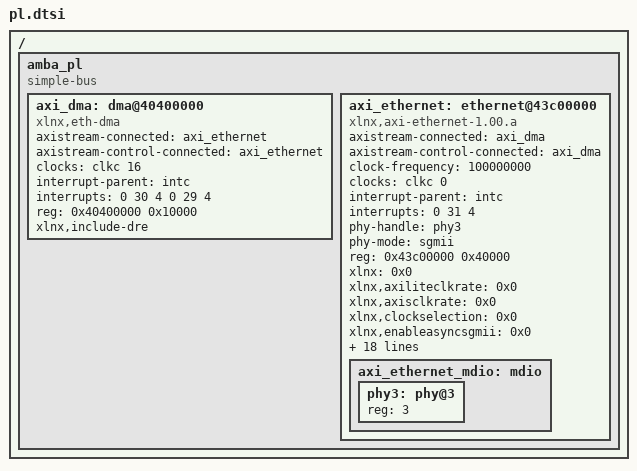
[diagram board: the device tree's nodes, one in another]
/*
 * CAUTION: This file is automatically generated by Xilinx.
 * Version:  
 * Today is: Thu Jan 31 15:05:06 2019
 */


/ {
	amba_pl: amba_pl {
		#address-cells = <1>;
		#size-cells = <1>;
		compatible = "simple-bus";
		ranges ;
		axi_dma: dma@40400000 {
			#dma-cells = <1>;
			axistream-connected = <&axi_ethernet>;
			axistream-control-connected = <&axi_ethernet>;
			clock-names = "s_axi_lite_aclk";
			clocks = <&clkc 16>;
			compatible = "xlnx,eth-dma";
			interrupt-names = "mm2s_introut", "s2mm_introut";
			interrupt-parent = <&intc>;
			interrupts = <0 30 4 0 29 4>;
			reg = <0x40400000 0x10000>;
			xlnx,include-dre ;
		};
		axi_ethernet: ethernet@43c00000 {
			axistream-connected = <&axi_dma>;
			axistream-control-connected = <&axi_dma>;
			clock-frequency = <100000000>;
			clock-names = "ref_clk";
			clocks = <&clkc 0>;
			compatible = "xlnx,axi-ethernet-1.00.a";
			device_type = "network";
			interrupt-names = "interrupt";
			interrupt-parent = <&intc>;
			interrupts = <0 31 4>;
			phy-handle = <&phy3>;
			phy-mode = "sgmii";
			reg = <0x43c00000 0x40000>;
			xlnx = <0x0>;
			xlnx,axiliteclkrate = <0x0>;
			xlnx,axisclkrate = <0x0>;
			xlnx,clockselection = <0x0>;
			xlnx,enableasyncsgmii = <0x0>;
			xlnx,gt-type = <0x0>;
			xlnx,gtinex = <0x0>;
			xlnx,gtlocation = <0x0>;
			xlnx,gtrefclksrc = <0x0>;
			xlnx,include-dre ;
			xlnx,instantiatebitslice0 = <0x0>;
			xlnx,phy-type = <0x5>;
			xlnx,phyaddr = <0x3>;
			xlnx,rable = <0x0>;
			xlnx,rxcsum = <0x2>;
			xlnx,rxlane0-placement = <0x0>;
			xlnx,rxlane1-placement = <0x0>;
			xlnx,rxmem = <0x4000>;
			xlnx,rxnibblebitslice0used = <0x1>;
			xlnx,tx-in-upper-nibble = <0x1>;
			xlnx,txcsum = <0x2>;
			xlnx,txlane0-placement = <0x0>;
			xlnx,txlane1-placement = <0x0>;
			axi_ethernet_mdio: mdio {
				#address-cells = <1>;
				#size-cells = <0>;
				phy3: phy@3 {
					device_type = "ethernet-phy";
					reg = <3>;
				};
			};
		};
	};
};
